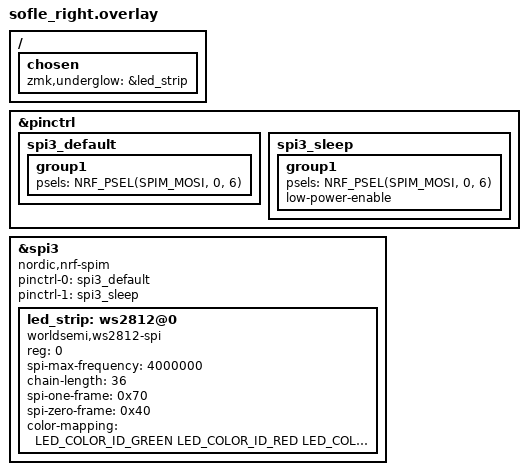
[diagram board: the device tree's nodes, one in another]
/*
 * RGB underglow (WS2812/SK6812) on the right half.
 * Data line on pro_micro pin 1 (D1) = P0.06. It was on D6/P1.00, but that pin
 * is also kscan row 1 (Q W E R T) - the SPI peripheral driving a pin the matrix
 * reads as an input made key scanning unreliable.
 * Driven over spi3 (unused by this shield) with MOSI remapped to that pin.
 */

#include <dt-bindings/led/led.h>

&pinctrl {
    spi3_default: spi3_default {
        group1 {
            psels = <NRF_PSEL(SPIM_MOSI, 0, 6)>;
        };
    };

    spi3_sleep: spi3_sleep {
        group1 {
            psels = <NRF_PSEL(SPIM_MOSI, 0, 6)>;
            low-power-enable;
        };
    };
};

&spi3 {
    compatible = "nordic,nrf-spim";
    status = "okay";

    pinctrl-0 = <&spi3_default>;
    pinctrl-1 = <&spi3_sleep>;
    pinctrl-names = "default", "sleep";

    led_strip: ws2812@0 {
        compatible = "worldsemi,ws2812-spi";

        /* SPI */
        reg = <0>; /* ignored, but necessary for SPI bindings */
        spi-max-frequency = <4000000>;

        /* WS2812 */
        /* Temporarily 36 (the Sofle RGB maximum) so the LOCATE effect can walk
         * past the real end of the chain and reveal how many LEDs are fitted.
         * Setting this higher than reality is harmless - the surplus data has
         * no LED left to latch it. Drop it to the real count once known. */
        chain-length = <36>;
        spi-one-frame = <0x70>;
        spi-zero-frame = <0x40>;

        color-mapping = <LED_COLOR_ID_GREEN LED_COLOR_ID_RED LED_COLOR_ID_BLUE>;
    };
};

/ {
    chosen {
        zmk,underglow = &led_strip;
    };
};
